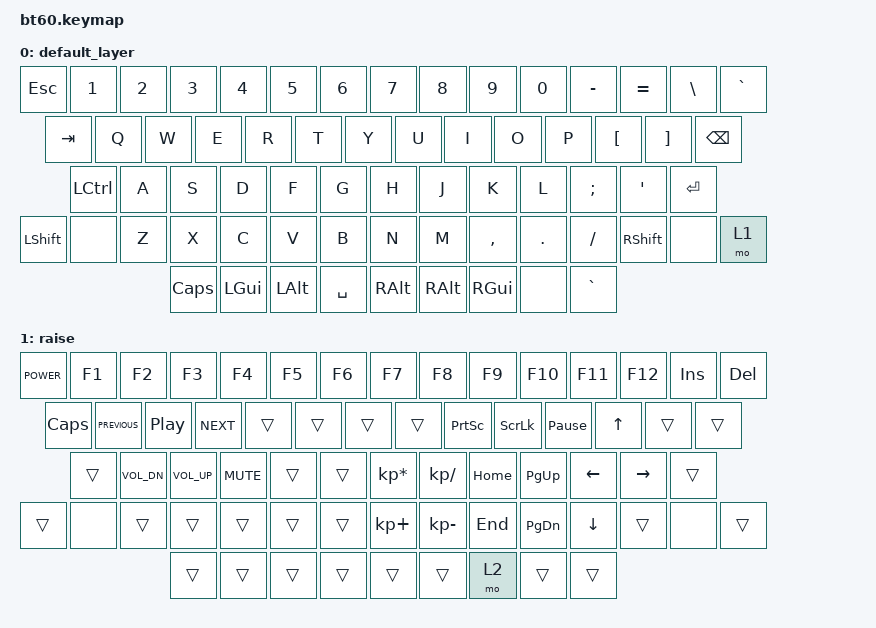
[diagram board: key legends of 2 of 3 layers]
#include <behaviors.dtsi>
#include <dt-bindings/zmk/keys.h>
#include <dt-bindings/zmk/bt.h>
#include <dt-bindings/zmk/rgb.h>
#include <dt-bindings/zmk/backlight.h>

/ {
	keymap {
		compatible = "zmk,keymap";

		default_layer {
				// ------------------------------------------------------------------------------------------
				// | ESC |  1  |  2  |  3  |  4  |  5  |  6  |  7  |  8  |  9  |  0  |  -  |  =  | BSLH | GRAVE |
				// | TAB  |  Q  |  W  |  E  |  R  |  T  |  Y  |  U  |  I  |  O  |  P  |  [  |  ]  |  |   BSPC
				// | CAPS  |  A  |  S  |  D  |  F  |  G  |  H  |  J  |  K  |  L  |  ;  |  '  |     ENTER    |
				// |  SHIFT|NONE|  Z  |  X  |  C  |  V  |  B  |  N  |  M  |  ,  |  .  | /   | SHFT | UP | 1  |
				// |  CTL  |  WIN  |  ALT  |            SPACE              | ALT | ALT | WIN | DOWN | RIGHT |
				// ------------------------------------------------------------------------------------------
			bindings = <
				&kp ESC &kp N1 &kp N2 &kp N3 &kp N4 &kp N5 &kp N6 &kp N7 &kp  N8   &kp  N9 &kp  N0  &kp MINUS &kp EQUAL &kp BSLH &kp GRAVE
				&kp TAB  &kp Q  &kp W  &kp E  &kp R  &kp T  &kp Y  &kp U  &kp  I    &kp  O  &kp  P   &kp LBKT &kp RBKT  &kp BSPC
				&kp LCTRL  &kp A  &kp S  &kp D  &kp F  &kp G  &kp H  &kp J  &kp  K    &kp  L  &kp SEMI &kp SQT           &kp RET
				&kp LSHFT &none  &kp Z  &kp X  &kp C  &kp V  &kp B  &kp N  &kp M  &kp COMMA &kp DOT &kp FSLH    &kp RSHFT &none   &mo 1
				&kp CLCK &kp LGUI &kp LALT            &kp SPACE                          &kp RALT  &kp RALT &kp RGUI &none &kp GRAVE
			>;
			sensor-bindings = <&inc_dec_kp C_VOL_UP C_VOL_DN>;
		};
		raise {
			//bindings = <
			//	&kp C_POWER &kp F1 &kp F2 &kp F3 &kp F4 &kp F5 &kp F6 &kp F7 &kp  F8   &kp  F9 &kp  F10  &kp F11 &kp F12   &kp INS &kp DEL
			//	&kp CLCK &kp C_PREVIOUS &kp C_PLAY_PAUSE &kp C_NEXT &trans &trans &trans &trans &kp PSCRN &kp SLCK &kp PAUSE_BREAK &kp UP &trans &trans
			//	&trans    &kp C_VOL_DOWN &kp C_VOL_UP &kp C_MUTE &trans &trans &kp MULTIPLY &kp DIVIDE &kp HOME &kp PAGE_UP &kp LEFT  &kp RIGHT   &trans
			//	&trans &none &trans &trans &trans &trans &trans &trans &kp PLUS &kp MINUS &kp END &kp PAGE_DOWN &kp DOWN &trans  &none &trans
			//	&trans &trans  &trans              &trans                            &trans  &trans &mo 2   &trans &trans
			//>;
			//sensor-bindings = <&inc_dec_kp C_VOL_UP C_VOL_DN>;
			bindings = <
				&kp C_POWER &kp F1 &kp F2 &kp F3 &kp F4 &kp F5 &kp F6 &kp F7 &kp  F8   &kp  F9 &kp  F10  &kp F11 &kp F12   &kp INS &kp DEL
				&kp CLCK &kp C_PREVIOUS &kp C_PLAY_PAUSE &kp C_NEXT &trans &trans &trans &trans &kp PSCRN &kp SLCK &kp PAUSE_BREAK &kp UP &trans &trans
				&trans    &kp C_VOL_DN &kp C_VOL_UP &kp C_MUTE &trans &trans &kp KP_MULTIPLY &kp KP_DIVIDE &kp HOME &kp PAGE_UP &kp LEFT  &kp RIGHT   &trans
				&trans &none &trans &trans &trans &trans &trans &kp KP_PLUS &kp KP_MINUS &kp END &kp PAGE_DOWN &kp DOWN &trans  &none &trans
				&trans &trans  &trans              &trans                            &trans  &trans &mo 2   &trans &trans
			>;
			sensor-bindings = <&inc_dec_kp C_VOL_UP C_VOL_DN>;
		};

		extra {
			bindings = <
				&bt BT_CLR &rgb_ug RGB_TOG &bl BL_TOG &trans &trans &trans &trans &trans &trans   &trans &trans  &trans &trans   &trans &trans
				&bt BT_SEL 0 &trans &trans &trans &trans &trans &trans &trans &trans &trans &trans &trans &trans &trans
				&bt BT_SEL 1    &trans &trans &trans &trans &trans &trans &trans &trans &trans &trans  &trans   &trans
				&bt BT_SEL 2 &none &bt BT_PRV &bt BT_NXT &trans &trans &trans &trans &trans &trans &trans &trans &trans &trans  &none &trans
				&bt BT_PRV &bt BT_SEL 3  &trans              &trans                            &trans  &trans &trans   &trans &trans
			>;
			sensor-bindings = <&inc_dec_kp C_VOL_UP C_VOL_DN>;
		};
	};
};
